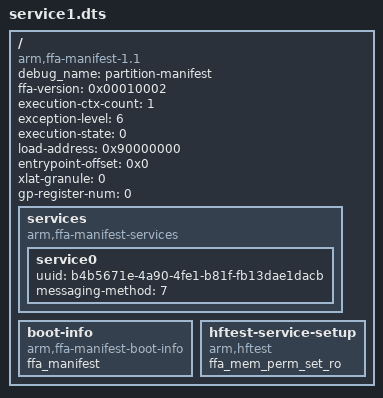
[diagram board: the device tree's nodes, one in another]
/*
 * Copyright 2023 The Hafnium Authors.
 *
 * Use of this source code is governed by a BSD-style
 * license that can be found in the LICENSE file or at
 * https://opensource.org/licenses/BSD-3-Clause.
 */

/dts-v1/;

/ {
	compatible = "arm,ffa-manifest-1.1";
	debug_name = "partition-manifest";

	/* Properties */
	ffa-version = <0x00010002>; /* 31:16 - Major, 15:0 - Minor */
	execution-ctx-count = <1>;
	exception-level = <6>; /* EL0 */
	execution-state = <0>; /* AARCH64 */
	load-address = <0x90000000>;
	entrypoint-offset = <0x0>;
	xlat-granule = <0>; /* 4KiB */
	gp-register-num = <0>;

	services {
		compatible = "arm,ffa-manifest-services";

		service0 {
			uuid = "b4b5671e-4a90-4fe1-b81f-fb13dae1dacb";
			messaging-method = <7>; /* Direct and indirect messaging */
		};
	};

	/* Boot Info */
	boot-info {
		compatible = "arm,ffa-manifest-boot-info";
		ffa_manifest;
	};

	hftest-service-setup {
		compatible = "arm,hftest";
		ffa_mem_perm_set_ro;
	};
};
